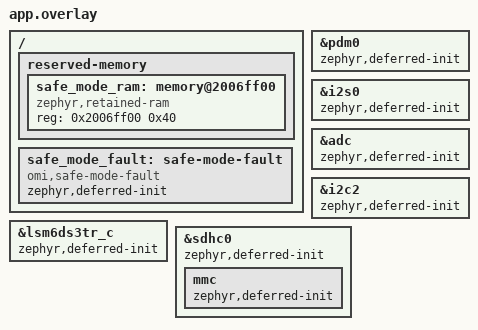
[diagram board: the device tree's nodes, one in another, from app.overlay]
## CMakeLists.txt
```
cmake_minimum_required(VERSION 3.20.0)
find_package(Zephyr REQUIRED HINTS $ENV{ZEPHYR_BASE})
enable_language(C ASM) # OPUS

project(omi)
include(cmake/safe-mode-build.cmake)
zephyr_linker_sources(SECTIONS src/safe_mode.ld)

file(GLOB app_sources
    src/main.c
    src/diagnostics.c
    src/diagnostics_packet.c
    src/boot_telemetry.c
    src/boot_telemetry_logic.c
    src/safe_mode.c
    src/safe_mode_devices.c
    src/mic.c
    src/battery.c
    src/led.c
    src/haptic.c
    src/sd_card.c
    src/spi_flash.c
    src/settings.c
    src/feedback.c
    src/wdog_facade.c
    src/rtc.c
    src/imu.c
)

if(CONFIG_OMI_ENABLE_T5838_AAD)
    # Hardware AAD is integrated into mic.c; t5838_aad.c is the low-level driver.
    list(APPEND app_sources src/t5838_aad.c)
endif()

if(CONFIG_OMI_SDHC_SPI_CMD12_FIX)
    # Zephyr's SPI SD host driver with the CMD12 reply fix, built instead of the stock one.
    list(APPEND app_sources src/sdfix/sdhc_spi_cmd12_fix.c)
endif()
file(GLOB core_sources
    src/lib/core/config.h
    src/lib/core/codec.c
    src/lib/core/custody.c
    src/lib/core/transport.c
    src/lib/core/battery_guard.c
    src/lib/core/button.c
    src/lib/core/capture_mute.c
    src/lib/core/monitor.c
    src/lib/core/unit_id.c
)

if(CONFIG_OMI_ENABLE_OFFLINE_STORAGE)
    list(APPEND core_sources src/lib/core/storage.c)
endif()

target_sources(app PRIVATE ${core_sources} ${app_sources})
target_include_directories(app PRIVATE
    ${CMAKE_CURRENT_SOURCE_DIR}/src
    ${CMAKE_CURRENT_SOURCE_DIR}/src/lib/core
    ${CMAKE_CURRENT_SOURCE_DIR}/../common
)

if(CONFIG_OMI_CODEC_OPUS)
    add_subdirectory(src/lib/core/lib/opus-1.2.1/)
    target_link_libraries(app PRIVATE opus_codec)
endif()
```

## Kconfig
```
source "Kconfig.zephyr"

menu "Omi Features Configuration"

config OMI_CODEC_OPUS
    bool "Opus Audio Codec"
    help
        "Enable the Opus audio codec support."
    default n

config OMI_ENABLE_OFFLINE_STORAGE
	bool "Offline SD Card Storage"
    help
        "Enable the offline storage support. Requires a SD Card."
	default n

config OMI_ENABLE_ACCELEROMETER
    bool "Accelerometer Support"
    help
        "Enable the accelerometer support."
    default n

config OMI_ENABLE_BUTTON
    bool "Button support"
    help
        "Enable the software button support."
    default n

config OMI_ENABLE_SPEAKER
    bool "Enable the speaker"
    help
        "Enable the speaker support."
    default n

config OMI_ENABLE_BATTERY
    bool "Enable the battery"
    help
        "Enable the battery support."
    default n

config OMI_ENABLE_USB
    bool "Enable the usb"
    help
        "Enable the USB power check support."
    default n

config OMI_ENABLE_HAPTIC
    bool "Enable the haptic"
    help
        "Enable the haptic support."
    default n

config OMI_ENABLE_RFSW_CTRL
    bool "Enable RFSwitch Control"
    help
        "Enable RFSwitch Control support."
    default y

config OMI_ENABLE_MONITOR
    bool "Enable monitoring/metrics system"
    help
        "Enable the monitoring system for debugging and metrics collection.
         Disable in production to save power, RAM, and flash space."
    default n

config OMI_ENABLE_T5838_AAD
    bool "Enable T5838 hardware AAD (ultra-low-power mic sleep)"
    default n
    help
        "After the configured silence interval, pause the PDM clock so the
         T5838 MEMS microphone enters its built-in Acoustic Activity Detection
         mode (~15 µA). The mic hardware monitors sound and asserts the WAKE
         pin when it detects acoustic activity, at which point the driver
         resumes PDM and audio streaming.
         Requires THSEL (P1.5) and WAKE (P1.2) to be wired to the T5838."

config OMI_VAD_ABS_THRESHOLD
    int "AAD silence-detection average absolute amplitude threshold"
    range 1 32767
    default 600
    depends on OMI_ENABLE_T5838_AAD
    help
        "An average absolute amplitude at or above this value resets the
         silence timer used to decide when to enter T5838 hardware AAD sleep.
         This does not gate or drop streamed audio while the mic is active."

config OMI_VAD_HOLD_MS
    int "AAD silence hold time before hardware sleep (ms)"
    range 500 30000
    default 3000
    depends on OMI_ENABLE_T5838_AAD
    help
        "Amount of continuous below-threshold silence before entering T5838
         hardware AAD sleep. This does not gate or drop streamed audio while
         the mic is active."

config OMI_AAD_SETTLE_MS
    int "T5838 AAD settle time before arming WAKE (ms)"
    range 100 3000
    default 800
    depends on OMI_ENABLE_T5838_AAD
    help
        "Time to wait after clocking the T5838 into hardware AAD sleep before
         arming the WAKE interrupt. Lets the mic settle its noise floor and
         swallow the entry transient so it does not immediately false-wake."

config OMI_WATCHDOG_TIMEOUT_MS
    int "Watchdog timeout (ms)"
    range 5000 300000
    default 30000
    help
        "Watchdog reset timeout in milliseconds. Increase this when boot-time
         operations can run longer (e.g. SD/LFS pre-warm) to avoid false
         watchdog resets."

config OMI_SDHC_SPI_CMD12_FIX
    bool "SPI SD host driver with the CMD12 reply fix"
    depends on DT_HAS_ZEPHYR_SDHC_SPI_SLOT_ENABLED
    depends on !SPI_SDHC
    select SPI
    select CRC
    select SDHC_SUPPORTS_SPI_MODE
    default n
    help
        "Builds src/sdfix/sdhc_spi_cmd12_fix.c, Zephyr's drivers/sdhc/sdhc_spi.c
         with the reply to CMD12 (STOP_TRANSMISSION) decoded even when it starts
         partway through a byte, instead of the stock driver. Without it every
         multi-block read fails with -EINVAL on cards that answer that way.
         Needs CONFIG_SPI_SDHC=n."
config OMI_SAFE_MODE_BOOT_LIMIT
    int "Failed boots before recovery"
    range 1 20
    default 3

config OMI_SAFE_MODE_GOOD_UPTIME_S
    int "Healthy main-loop uptime before GOOD (seconds)"
    range 1 3600
    default 60

config OMI_FAULT_INJECT
    bool "DEVELOPMENT ONLY: safe-mode fault injection"
    depends on DEBUG
    default n
    help
      Also requires -DOMI_DEVELOPMENT_BUILD=ON. Release builds reject this.

choice OMI_FAULT_INJECT_KIND
    prompt "Fault to inject on every normal trial"
    depends on OMI_FAULT_INJECT
    default OMI_FAULT_INJECT_HARD_FAULT

config OMI_FAULT_INJECT_HARD_FAULT
    bool "Fatal error before BLE"
config OMI_FAULT_INJECT_DRIVER_HANG
    bool "Deferred driver-init hang"
config OMI_FAULT_INJECT_SETTINGS_HANG
    bool "Hang in app_settings_init"
config OMI_FAULT_INJECT_WDT_STARVE
    bool "Stop feeding WDT at uptime 30 seconds"
endchoice

config OMI_FAULT_INJECT_HARD_FAULT_DELAY_MS
    int "Dwell before the injected fatal error"
    depends on OMI_FAULT_INJECT_HARD_FAULT
    default 0
    help
      Sleep this long between the fault witness line and the fatal error,
      still before BLE, so a bench observer polling over SWD can sample the
      witness on every failing boot.

endmenu
```

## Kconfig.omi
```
menu "Omi2 Features Configuration"

config OMI2_CODEC_OPUS
    bool "Opus Audio Codec"
    help
        "Enable the Opus audio codec support."
    default n

config OMI2_ENABLE_OFFLINE_STORAGE
    bool "Offline SD Card Storage"
    select DISK_ACCESS
    select FILE_SYSTEM
    select FAT_FILESYSTEM_ELM
    select FS_FATFS_MOUNT_MKFS
    select FS_FATFS_EXFAT
    help
        "Enable the offline storage support. Requires a SD Card."
    default n

config OMI2_ENABLE_ACCELEROMETER
    bool "Accelerometer Support"
    help
        "Enable the accelerometer support."
    default n

config OMI2_ENABLE_BUTTON
    bool "Button support"
    help
        "Enable the software button support."
    default n

config OMI2_ENABLE_SPEAKER
    bool "Enable the speaker"
    help
        "Enable the speaker support."
    default n

config OMI2_ENABLE_BATTERY
    bool "Enable the battery"
    help
        "Enable the battery support."
    default n

config OMI2_ENABLE_USB
    bool "Enable the usb"
    help
        "Enable the USB power check support."
    default n

config OMI2_ENABLE_HAPTIC
    bool "Enable the haptic"
    help
        "Enable the haptic support."
    default n

endmenu
```

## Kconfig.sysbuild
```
#
# Copyright (c) 2023 Nordic Semiconductor
#
# SPDX-License-Identifier: LicenseRef-Nordic-5-Clause
#

source "${ZEPHYR_BASE}/share/sysbuild/Kconfig"

config NRF_DEFAULT_IPC_RADIO
	default y

config NETCORE_IPC_RADIO_BT_HCI_IPC
	default y
```

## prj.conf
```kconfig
CONFIG_SERIAL=y

CONFIG_GPIO=y
CONFIG_INPUT=y
CONFIG_I2C=y
# CONFIG_I2C_SHELL=y
CONFIG_SPI=y
CONFIG_SPI_NOR=y
# CONFIG_SPI_SHELL=y
CONFIG_SETTINGS=y
CONFIG_SETTINGS_NVS=y
CONFIG_NVS=y

CONFIG_PM_DEVICE=y
# CONFIG_PM_DEVICE_RUNTIME=y
CONFIG_ADC=y
CONFIG_ADC_ASYNC=y
CONFIG_ADC_NRFX_SAADC=y
CONFIG_AUDIO=y
CONFIG_AUDIO_DMIC=y
CONFIG_FLASH=y
CONFIG_FLASH_JESD216_API=y
CONFIG_DISK_DRIVER_SDMMC=y
CONFIG_SENSOR=y
CONFIG_REGULATOR=y
CONFIG_ENTROPY_GENERATOR=y

CONFIG_BT=y
CONFIG_BT_SMP=y
CONFIG_BT_PERIPHERAL=y
CONFIG_BT_DIS=n
CONFIG_BT_BAS=n
# CONFIG_BT_DEVICE_NAME="OMI" # configurated bellow
# CONFIG_BT_DEVICE_APPEARANCE=768 # TODO: conflict
CONFIG_CBPRINTF_FP_SUPPORT=y

CONFIG_NCS_SAMPLE_MCUMGR_BT_OTA_DFU=y
CONFIG_MCUMGR_GRP_IMG_ALLOW_ERASE_PENDING=y
# BT NUS shell: controlled by CONFIG_OMI_ENABLE_BT_LOG
CONFIG_SHELL=y
CONFIG_SHELL_BT_NUS=n
CONFIG_SHELL_BT_NUS_LOG_LEVEL_INF=n
CONFIG_SHELL_LOG_BACKEND=y
# CONFIG_SHELL_BACKEND_DUMMY=y

CONFIG_POWEROFF=y

# CONFIG_T5838_LOG_LEVEL_DBG=y
# CONFIG_T5838_AAD_TRIGGER=y

# file system
# CONFIG_MAIN_STACK_SIZE=2048
CONFIG_FILE_SYSTEM=y
# CONFIG_FILE_SYSTEM_EXT2=y

# LittleFS formats itself on first mount - no explicit mkfs needed
# CONFIG_FILE_SYSTEM_MKFS is not set
# CONFIG_FS_FATFS_MKFS is not set
# CONFIG_TEST_RANDOM_GENERATOR=y

CONFIG_DISK_ACCESS=y
CONFIG_DISK_DRIVER_SDMMC=y

# FAT filesystem automatically detects partitions
# CONFIG_EXT2_DISK_STARTING_SECTOR=2082

# Memories
CONFIG_MAIN_STACK_SIZE=4096
CONFIG_SYSTEM_WORKQUEUE_STACK_SIZE=4096

# Kernel options
CONFIG_ENTROPY_GENERATOR=y
CONFIG_POSIX_CLOCK=y

CONFIG_INIT_STACKS=y
CONFIG_HEAP_MEM_POOL_SIZE=40000

#
# Hardware settings
#

CONFIG_PWM=y
CONFIG_GPIO=y
CONFIG_ADC=y

#
# Audio (new)
#
CONFIG_I2S=y
CONFIG_I2S_NRFX=y
CONFIG_SPI_NRFX=y
CONFIG_AUDIO=y
CONFIG_AUDIO_DMIC=y
CONFIG_AUDIO_DMIC_NRFX_PDM=y
CONFIG_NRFX_PDM0=y  # PDM microphone

# Watchdog Timer
CONFIG_WATCHDOG=y
CONFIG_WDT_DISABLE_AT_BOOT=n

# To flash via dev board
#CONFIG_BUILD_OUTPUT_UF2=n
#CONFIG_USE_DT_CODE_PARTITION=n

#
# Bluetooth settings
#

CONFIG_BT=y
CONFIG_BT_PERIPHERAL=y
CONFIG_BT_MAX_CONN=1
# CONFIG_BT_EXT_ADV_MAX_ADV_SET=2
CONFIG_BT_MAX_PAIRED=1
CONFIG_BT_DEVICE_APPEARANCE=22
CONFIG_BT_GATT_DYNAMIC_DB=y

#
# Max transmit power supported by nRF52840
#

CONFIG_BT_CTLR_TX_PWR_ANTENNA=8
CONFIG_BT_PHY_UPDATE=y

#
# Battery and Device Information services
#

CONFIG_BT_BAS=y
CONFIG_BT_DIS=y
CONFIG_BT_DIS_PNP=n
CONFIG_BT_DEVICE_NAME="Omi"
CONFIG_BT_DIS_MODEL="Omi CV 1"
CONFIG_BT_DIS_MANUF="Based Hardware"
CONFIG_BT_DIS_FW_REV=y
CONFIG_BT_DIS_HW_REV=y
CONFIG_BT_DIS_FW_REV_STR="3.0.15"
CONFIG_BT_DIS_HW_REV_STR="5.0"

#
# Large BLE packets / BLE Buffers 
#
# CONFIG_BT_GATT_CLIENT=y
# CONFIG_BT_THROUGHPUT=y

CONFIG_BT_L2CAP_TX_MTU=498

CONFIG_BT_CTLR_DATA_LENGTH_MAX=251
CONFIG_BT_CTLR_PHY_2M=y
CONFIG_BT_CTLR_PHY_CODED=y
CONFIG_BT_CTLR_SDC_MAX_CONN_EVENT_LEN_DEFAULT=400000
CONFIG_BT_CONN_TX_MAX=20
CONFIG_BT_L2CAP_TX_BUF_COUNT=20
CONFIG_BT_BUF_ACL_RX_SIZE=1024
CONFIG_BT_BUF_ACL_TX_SIZE=2048
CONFIG_BT_ATT_TX_COUNT=20
# CONFIG_BT_EXT_ADV=y
# CONFIG_BT_PER_ADV=y
# CONFIG_BT_OBSERVER=y
# CONFIG_BT_ATT_PREPARE_COUNT=2
CONFIG_BT_USER_DATA_LEN_UPDATE=y
CONFIG_BT_USER_PHY_UPDATE=y
CONFIG_BT_AUTO_DATA_LEN_UPDATE=y
CONFIG_BT_AUTO_PHY_UPDATE=y
CONFIG_BT_GATT_AUTO_UPDATE_MTU=y

CONFIG_BT_GATT_CLIENT=y

# Automatically request preferred connection parameters (default is y, but explicit)
CONFIG_BT_GAP_AUTO_UPDATE_CONN_PARAMS=y

# Set preferred connection parameters
# 7.5ms
CONFIG_BT_PERIPHERAL_PREF_MIN_INT=6
# 15ms (was 30ms — tighter interval = more events/sec = higher throughput)
CONFIG_BT_PERIPHERAL_PREF_MAX_INT=12
CONFIG_BT_PERIPHERAL_PREF_LATENCY=0
# 4 seconds
CONFIG_BT_PERIPHERAL_PREF_TIMEOUT=400

CONFIG_FPU=y
CONFIG_NORDIC_QSPI_NOR=y
# CONFIG_BOARD_ENABLE_DCDC=y
#

#
# Console
#
# Y to enable console log
CONFIG_CONSOLE=y
CONFIG_PRINTK=y
CONFIG_UART_CONSOLE=y
# CONFIG_SHELL_BACKEND_SERIAL=y

#
# Logs
#

## Enable the lines below to enable logs via UART/USB
CONFIG_LOG=y
CONFIG_LOG_PRINTK=y
CONFIG_UART_CONSOLE=y
CONFIG_LOG_PROCESS_THREAD_PRIORITY=5
CONFIG_LOG_PROCESS_THREAD_CUSTOM_PRIORITY=y
#
# CONFIG_LOG_MODE_IMMEDIATE=y
# CONFIG_SENSOR_LOG_LEVEL_DBG=y
# CONFIG_FLASH_LOG_LEVEL_DBG=y
# CONFIG_FS_LOG_LEVEL_DBG=y


#
# Enable logging (set level to DBG=4, INF=3, WRN=2, ERR=1)
# CONFIG_LOG_DEFAULT_LEVEL=3

#
# Log level and buffer size
#

# CONFIG_LOG_OVERRIDE_LEVEL=4
# CONFIG_LOG_BUFFER_SIZE=32000
# CONFIG_LOG_PROCESS_THREAD_STACK_SIZE=4096

#
# Debug
#

# CONFIG_DEBUG=y
# CONFIG_DEBUG_OPTIMIZATIONS=y
# CONFIG_SERIAL=y

#
# Debug (This value breaks some builds)
#

# CONFIG_ASSERT=y

#
# BT log configuration
#

# CONFIG_BT_DEBUG_LOG=y
# CONFIG_BT_L2CAP_LOG_LEVEL_DBG=y
# CONFIG_BT_LOG_LEVEL_DBG=y

# CONFIG_BT_RX_STACK_SIZE=4096
# CONFIG_BT_CTLR_RX_PRIO_STACK_SIZE=4096
# CONFIG_BT_DEBUG_LOG=y
# CONFIG_BT_RX_STACK_SIZE=4096
# CONFIG_BT_CTLR_RX_PRIO_STACK_SIZE=4096

#
# SD Card Support (all devices required)
#

CONFIG_DISK_ACCESS=y
CONFIG_FILE_SYSTEM=y

# LittleFS for SD NAND (power-loss safe, no FAT dirty-bit issues)
CONFIG_FILE_SYSTEM_LITTLEFS=y

# FAT disabled - SD NAND + FATFS is unstable (no wear leveling, power-loss unsafe)
# CONFIG_FAT_FILESYSTEM_ELM is not set
# CONFIG_FS_FATFS_MOUNT_MKFS is not set
CONFIG_MAIN_STACK_SIZE=4096
CONFIG_DISK_DRIVER_SDMMC=y
# CONFIG_SPI=y
# CONFIG_HEAP_MEM_POOL_SIZE=512 # disabled by conflicting

#
# Disable unused peripherals
#
CONFIG_I2C=n
# CONFIG_NRFX_TWIM0=n
# CONFIG_NRFX_TWIM1=n

#
# LSM6DSL sensor (accelerometer and gyroscope)
#
CONFIG_LSM6DSL=y
CONFIG_LSM6DSL_ENABLE_TEMP=n
# CONFIG_LSM6DSL_TRIGGER_GLOBAL_THREAD=y
CONFIG_SENSOR=y

#
# Speaker
#
CONFIG_I2S=y
CONFIG_I2S_NRFX=y
CONFIG_SPI_NRFX=y

#
# NFC (in the future)
#

# CONFIG_NFC_T2T_NRFXLIB=y
# CONFIG_NFC_NDEF=y
# CONFIG_NFC_NDEF_MSG=y
# CONFIG_NFC_NDEF_RECORD=y
# CONFIG_NFC_NDEF_URI_MSG=y
# CONFIG_NFC_NDEF_URI_REC=y
# CONFIG_HWINFO=y

#
#EVERYTHING ELSE
#

CONFIG_RING_BUFFER=y

CONFIG_PM_DEVICE=y
# CONFIG_NRFX_USBD=y

# CONFIG_FLASH=y
#

#
# OMI features configuration
#
CONFIG_OMI_CODEC_OPUS=y
CONFIG_OMI_ENABLE_OFFLINE_STORAGE=y
CONFIG_OMI_ENABLE_ACCELEROMETER=n
CONFIG_OMI_ENABLE_BUTTON=y
CONFIG_OMI_ENABLE_SPEAKER=n
CONFIG_OMI_ENABLE_BATTERY=y
CONFIG_OMI_ENABLE_USB=n
CONFIG_OMI_ENABLE_HAPTIC=y
CONFIG_OMI_ENABLE_RFSW_CTRL=y
CONFIG_OMI_ENABLE_MONITOR=n
```

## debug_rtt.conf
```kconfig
# Debug overlay for AAD bring-up.
# Routes logs + console to SEGGER RTT so they can be read over the debugger
# with no UART wiring. APPROTECT is left unlocked (default) for SWD access.

CONFIG_USE_SEGGER_RTT=y
CONFIG_LOG_BACKEND_RTT=y
CONFIG_LOG_BACKEND_UART=n
CONFIG_RTT_CONSOLE=y
CONFIG_UART_CONSOLE=n
CONFIG_SEGGER_RTT_BUFFER_SIZE_UP=16384
CONFIG_LOG_BACKEND_RTT_MODE_BLOCK=y
CONFIG_LOG_BUFFER_SIZE=8192
CONFIG_LOG_DEFAULT_LEVEL=3

# Shorten VAD hold so the device drops into hardware AAD after 3s of silence
# (default 10s) for faster test iteration.
CONFIG_OMI_VAD_HOLD_MS=3000
```

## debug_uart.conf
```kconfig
# Debug overlay: log over UART console (P0.03 TX / P0.02 RX @115200) instead of RTT.
# prj.conf already enables CONFIG_LOG + CONFIG_UART_CONSOLE.
CONFIG_OMI_VAD_HOLD_MS=10000
CONFIG_OMI_AAD_SETTLE_MS=800
CONFIG_OMI_DEBUG_FAKE_RTC=y
CONFIG_OMI_AAD_TEST_MODE=0
CONFIG_OMI_AAD_POWER_OFF_MIC=n
```

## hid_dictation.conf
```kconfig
# Omi CV1 HID dictation PROTOTYPE build overlay.
#
# NOT for production: append to the production omi.conf via
#   west build ... -- -DEXTRA_CONF_FILE=<this file>
# or use scripts/ci/build-cv1-hid-prototype.sh, which wires everything up.
#
# What this changes vs. the stock build:
#  - compiles in the opt-in dictation control-plane + (after an explicit,
#    RAM-only app opt-in) a standard BLE HID keyboard service;
#  - HID characteristics require an encrypted link (standard for HID hosts);
#  - bond storage enabled so a paired HID host can reconnect;
#  - GAP appearance becomes "keyboard" so hosts classify the pendant.
# Stock behavior is unchanged until the app enables the prototype, and a
# power cycle always clears the opt-in (documented recovery path).

CONFIG_OMI_ENABLE_HID_DICTATION=y

CONFIG_BT_HIDS=y
CONFIG_BT_CONN_CTX=y
CONFIG_BT_HIDS_MAX_CLIENT_COUNT=1
CONFIG_BT_HIDS_INPUT_REP_MAX=1
CONFIG_BT_HIDS_OUTPUT_REP_MAX=1
CONFIG_BT_HIDS_DEFAULT_PERM_RW_ENCRYPT=y

CONFIG_BT_GATT_SERVICE_CHANGED=y
CONFIG_BT_SETTINGS=y
CONFIG_BT_KEYS_OVERWRITE_OLDEST=y

CONFIG_BT_DEVICE_APPEARANCE=961
```

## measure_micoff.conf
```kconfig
# Power measurement: force the mic into hardware AAD sleep forever (mic-off floor).
CONFIG_OMI_AAD_TEST_MODE=1
CONFIG_OMI_VAD_HOLD_MS=1000
CONFIG_OMI_AAD_SETTLE_MS=800
```

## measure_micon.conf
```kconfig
# Power measurement: mic runs continuously, never enters AAD (mic-on floor = soft AAD).
CONFIG_OMI_AAD_TEST_MODE=2
```

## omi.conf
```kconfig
CONFIG_SERIAL=y
CONFIG_GPIO=y
CONFIG_PWM=y
CONFIG_INPUT=y
CONFIG_I2C=y
CONFIG_SPI=y
CONFIG_SPI_NOR=y
CONFIG_SETTINGS=y
CONFIG_SETTINGS_NVS=y
CONFIG_NVS=y

CONFIG_PM_DEVICE=y
CONFIG_ADC=y
CONFIG_ADC_ASYNC=y
CONFIG_ADC_NRFX_SAADC=y
CONFIG_AUDIO=y
CONFIG_AUDIO_DMIC=y
CONFIG_FLASH=y
CONFIG_FLASH_JESD216_API=y
CONFIG_DISK_DRIVER_SDMMC=y
CONFIG_SENSOR=y
CONFIG_REGULATOR=y
CONFIG_ENTROPY_GENERATOR=y

CONFIG_RING_BUFFER=y

CONFIG_BT=y
CONFIG_BT_SMP=y
CONFIG_BT_PERIPHERAL=y
CONFIG_BT_DIS=n
CONFIG_BT_BAS=n
# CONFIG_BT_DEVICE_NAME="OMI" # configurated bellow
# CONFIG_BT_DEVICE_APPEARANCE=768 # TODO: conflict
CONFIG_CBPRINTF_FP_SUPPORT=y

CONFIG_NCS_SAMPLE_MCUMGR_BT_OTA_DFU=y
CONFIG_MCUMGR_GRP_IMG_ALLOW_ERASE_PENDING=y
# BT NUS shell: controlled by CONFIG_OMI_ENABLE_BT_LOG
CONFIG_SHELL=n
CONFIG_SHELL_BT_NUS=n
CONFIG_SHELL_BT_NUS_LOG_LEVEL_INF=n
CONFIG_SHELL_LOG_BACKEND=n

CONFIG_POWEROFF=y

# file system
# CONFIG_MAIN_STACK_SIZE=2048
CONFIG_FILE_SYSTEM=y
CONFIG_DISK_ACCESS=y
CONFIG_DISK_DRIVER_SDMMC=y
# SD card over SPI: Zephyr's driver with the CMD12 reply fix (src/sdfix), not the stock one.
CONFIG_SPI_SDHC=n
CONFIG_OMI_SDHC_SPI_CMD12_FIX=y

# Memories
CONFIG_MAIN_STACK_SIZE=4096
CONFIG_SYSTEM_WORKQUEUE_STACK_SIZE=4096

# Kernel options
CONFIG_ENTROPY_GENERATOR=y
CONFIG_POSIX_CLOCK=y

CONFIG_INIT_STACKS=y
CONFIG_HEAP_MEM_POOL_SIZE=40000

#
# Audio (new)
#
CONFIG_I2S=y
CONFIG_I2S_NRFX=y
CONFIG_SPI_NRFX=y
CONFIG_AUDIO=y
CONFIG_AUDIO_DMIC=y
CONFIG_AUDIO_DMIC_NRFX_PDM=y
CONFIG_NRFX_PDM0=y  # PDM microphone

# Watchdog Timer
CONFIG_WATCHDOG=y
CONFIG_WDT_DISABLE_AT_BOOT=n

# To flash via dev board
#CONFIG_BUILD_OUTPUT_UF2=n
#CONFIG_USE_DT_CODE_PARTITION=n

#
# Bluetooth settings
#

CONFIG_BT=y
CONFIG_BT_PERIPHERAL=y
CONFIG_BT_MAX_CONN=1
CONFIG_BT_MAX_PAIRED=1
CONFIG_BT_DEVICE_APPEARANCE=22
CONFIG_BT_GATT_DYNAMIC_DB=y
CONFIG_BT_DEVICE_NAME_DYNAMIC=y

#
# nRF5340 BLE controller settings (network core)
#

# BT_CTLR_* options take effect on the network core via sysbuild/ipc_radio.conf,
# not this app-core config. Keep controller tuning in that image configuration.
CONFIG_BT_CTLR_TX_PWR_ANTENNA=8
CONFIG_BT_PHY_UPDATE=y

#
# Battery and Device Information services
#

CONFIG_BT_BAS=y
CONFIG_BT_DIS=y
CONFIG_BT_DIS_PNP=n
CONFIG_BT_DEVICE_NAME="Omi"
CONFIG_BT_DIS_MODEL="Omi CV 1"
CONFIG_BT_DIS_MANUF="Based Hardware"
CONFIG_BT_DIS_FW_REV=y
CONFIG_BT_DIS_HW_REV=y
CONFIG_BT_DIS_FW_REV_STR="3.0.24"
CONFIG_BT_DIS_HW_REV_STR="5.0"
# Per-unit serial (0x2A25) = FICR device ID, set at boot by unit_id.c through
# the DIS settings handler. The static string is only a fallback.
CONFIG_BT_DIS_SERIAL_NUMBER=y
CONFIG_BT_DIS_SERIAL_NUMBER_STR="unknown"
CONFIG_BT_DIS_SETTINGS=y
CONFIG_SETTINGS_RUNTIME=y
CONFIG_HWINFO=y

#
# Large BLE packets / BLE Buffers 
#
# CONFIG_BT_GATT_CLIENT=y
# CONFIG_BT_THROUGHPUT=y

CONFIG_BT_L2CAP_TX_MTU=498

CONFIG_BT_CTLR_DATA_LENGTH_MAX=251
CONFIG_BT_CTLR_PHY_2M=y
CONFIG_BT_CTLR_PHY_CODED=y
CONFIG_BT_CTLR_SDC_MAX_CONN_EVENT_LEN_DEFAULT=400000
CONFIG_BT_CONN_TX_MAX=20
CONFIG_BT_L2CAP_TX_BUF_COUNT=20
CONFIG_BT_BUF_ACL_RX_SIZE=1024
CONFIG_BT_BUF_ACL_TX_SIZE=2048
CONFIG_BT_BUF_ACL_TX_COUNT=10
CONFIG_BT_ATT_TX_COUNT=20
CONFIG_BT_USER_DATA_LEN_UPDATE=y
CONFIG_BT_USER_PHY_UPDATE=y
CONFIG_BT_AUTO_DATA_LEN_UPDATE=y
CONFIG_BT_AUTO_PHY_UPDATE=y
CONFIG_BT_GATT_AUTO_UPDATE_MTU=y

CONFIG_BT_GATT_CLIENT=y

# Automatically request preferred connection parameters (default is y, but explicit)
CONFIG_BT_GAP_AUTO_UPDATE_CONN_PARAMS=y

# Set preferred connection parameters
# 7.5ms
CONFIG_BT_PERIPHERAL_PREF_MIN_INT=6
# 15ms (was 30ms — tighter interval = more events/sec = higher throughput)
CONFIG_BT_PERIPHERAL_PREF_MAX_INT=12
CONFIG_BT_PERIPHERAL_PREF_LATENCY=0
# 6 seconds
CONFIG_BT_PERIPHERAL_PREF_TIMEOUT=600

CONFIG_FPU=y
CONFIG_NORDIC_QSPI_NOR=y
CONFIG_BOARD_ENABLE_DCDC_APP=y
CONFIG_BOARD_ENABLE_DCDC_NET=y

#
# Console
#
# Y to enable console log
CONFIG_CONSOLE=y
CONFIG_PRINTK=y
CONFIG_UART_CONSOLE=y
# CONFIG_SHELL_BACKEND_SERIAL=y

# Keep release output minimal: only explicit printk() lines.
CONFIG_LOG=n

#
# Logs
#

## Enable the lines below to enable logs via UART/USB
# CONFIG_LOG=y
# CONFIG_LOG_PRINTK=y
# CONFIG_UART_CONSOLE=y
# CONFIG_LOG_PROCESS_THREAD_PRIORITY=5
# CONFIG_LOG_PROCESS_THREAD_CUSTOM_PRIORITY=y
#
# CONFIG_LOG_MODE_IMMEDIATE=y
# CONFIG_SENSOR_LOG_LEVEL_DBG=y
# CONFIG_FLASH_LOG_LEVEL_DBG=y
# CONFIG_FS_LOG_LEVEL_DBG=y


#
# Enable logging (set level to DBG=4, INF=3, WRN=2, ERR=1)
# CONFIG_LOG_DEFAULT_LEVEL=3

# LittleFS is currently unused by CV1 storage.
# src/sd_card.c uses a raw-sector SD NAND ring with no filesystem.
CONFIG_FILE_SYSTEM_LITTLEFS=y

#
# Disable unused peripherals
#
CONFIG_I2C=n
# CONFIG_NRFX_TWIM0=n
# CONFIG_NRFX_TWIM1=n

#
# LSM6DSL sensor (accelerometer and gyroscope)
#
CONFIG_LSM6DSL=y
CONFIG_LSM6DSL_ENABLE_TEMP=n

#
# OMI features configuration
#
CONFIG_OMI_CODEC_OPUS=y
CONFIG_OMI_ENABLE_OFFLINE_STORAGE=y
CONFIG_OMI_ENABLE_ACCELEROMETER=n
CONFIG_OMI_ENABLE_BUTTON=y
CONFIG_OMI_ENABLE_SPEAKER=n
CONFIG_OMI_ENABLE_BATTERY=y
CONFIG_OMI_ENABLE_USB=n
CONFIG_OMI_ENABLE_HAPTIC=y
CONFIG_OMI_ENABLE_RFSW_CTRL=y
CONFIG_OMI_ENABLE_MONITOR=n
CONFIG_OMI_ENABLE_T5838_AAD=y
# Silence threshold + hold used only to decide when to enter hardware AAD sleep.
CONFIG_OMI_VAD_ABS_THRESHOLD=250
CONFIG_OMI_VAD_HOLD_MS=10000
CONFIG_OMI_AAD_SETTLE_MS=800

# App-owned recovery observes completed image uploads.
CONFIG_MCUMGR_MGMT_NOTIFICATION_HOOKS=y
CONFIG_MCUMGR_GRP_IMG_STATUS_HOOKS=y

CONFIG_MCUMGR_GRP_IMG_UPLOAD_CHECK_HOOK=y
```

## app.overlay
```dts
/* App only: the shared board DTS and MCUboot's DTS remain unchanged. */
/ {
    reserved-memory {
        #address-cells = <1>;
        #size-cells = <1>;
        ranges;
        safe_mode_ram: memory@2006ff00 {
            compatible = "zephyr,retained-ram";
            reg = <0x2006ff00 0x40>;
        };
    };
};

/* Application only. Recovery never invokes these devices' init functions. */
&pdm0 { zephyr,deferred-init; };
&i2s0 { zephyr,deferred-init; };
&adc { zephyr,deferred-init; };
&i2c2 { zephyr,deferred-init; };
&lsm6ds3tr_c { zephyr,deferred-init; };
&sdhc0 {
    zephyr,deferred-init;
    mmc { zephyr,deferred-init; };
};

/ {
    safe_mode_fault: safe-mode-fault {
        compatible = "omi,safe-mode-fault";
        zephyr,deferred-init;
    };
};
```

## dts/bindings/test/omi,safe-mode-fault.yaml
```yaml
description: Development-only deferred-init hang witness
compatible: "omi,safe-mode-fault"
include: base.yaml
```

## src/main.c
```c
#include <zephyr/kernel.h>
#include <zephyr/logging/log.h>
#include <zephyr/pm/device_runtime.h>
#include <zephyr/shell/shell.h>

#include "lib/core/button.h"
#include "lib/core/codec.h"
#include "lib/core/config.h"
#include "lib/core/feedback.h"
#include "lib/core/haptic.h"
#include "lib/core/led.h"
#include "lib/core/lib/battery/battery.h"
#include "lib/core/mic.h"
#ifdef CONFIG_OMI_ENABLE_MONITOR
#include "lib/core/monitor.h"
#endif
#include "lib/core/settings.h"
#include "lib/core/transport.h"
#ifdef CONFIG_OMI_ENABLE_OFFLINE_STORAGE
#include "lib/core/storage.h"
#endif
#ifndef CONFIG_OMI_NATIVE_SIM
#include <zephyr/fatal.h>
#endif

#include "imu.h"
#include "lib/core/sd_card.h"
#include "rtc.h"
#include "safe_mode.h"
#include "spi_flash.h"
#include "wdog_facade.h"

LOG_MODULE_REGISTER(main, CONFIG_LOG_DEFAULT_LEVEL);

#ifdef CONFIG_OMI_ENABLE_BATTERY
#define BATTERY_FULL_THRESHOLD_PERCENT 98 // 98%
extern uint8_t battery_percentage;
#endif
bool is_connected = false;
bool is_charging = false;
bool is_off = false;
bool blink_toggle = false;

static void codec_handler(uint8_t *data, size_t len)
{
#ifdef CONFIG_OMI_ENABLE_MONITOR
    monitor_inc_broadcast_audio();
#endif
    int err = broadcast_audio_packets(data, len);
    if (err) {
#ifdef CONFIG_OMI_ENABLE_MONITOR
        monitor_inc_broadcast_audio_failed();
#endif
    }
}

static void mic_handler(int16_t *buffer)
{
#ifdef CONFIG_OMI_ENABLE_MONITOR
    // Track total bytes processed (each sample is 2 bytes)
    monitor_inc_mic_buffer();
#endif

    // Hardware AAD (T5838) is handled inside mic.c; the mic callback only
    // forwards audio to the codec here.
    int err = codec_receive_pcm(buffer, MIC_BUFFER_SAMPLES);
    if (err) {
        LOG_ERR("Failed to process PCM data: %d", err);
    }
}

void set_led_state()
{
    // If device is off, turn off all LEDs immediately
    if (is_off) {
        led_off();
        return;
    }

#ifdef CONFIG_OMI_ENABLE_OFFLINE_STORAGE
    // If RTC not synced, blink red to warn user to connect phone app
    if (!rtc_is_valid()) {
        set_led_green(is_charging);
        set_led_blue(!blink_toggle && is_connected);
        set_led_red(blink_toggle);
        blink_toggle = !blink_toggle;
        return;
    }
#endif

    bool green = false;
    bool blue = false;
    bool red = false;

    if (is_charging) {
#ifdef CONFIG_OMI_ENABLE_BATTERY
        // Solid green if battery is full (>= BATTERY_FULL_THRESHOLD_PERCENT)
        if (battery_percentage >= BATTERY_FULL_THRESHOLD_PERCENT) {
            green = true;
        } else
#endif
        {
            green = blink_toggle;
            blue = !blink_toggle && is_connected;
            red = !blink_toggle && !is_connected;
            blink_toggle = !blink_toggle;
        }
    } else {
        blue = is_connected;
        red = !is_connected;
    }

    set_led_green(green);
    set_led_blue(blue);
    set_led_red(red);
}

static int suspend_unused_modules(void)
{
    int err = flash_off();
    if (err) {
        LOG_ERR("Can not suspend the spi flash module: %d", err);
    }

    return 0;
}

int main(void)
{
    int ret;
    printk("Starting omi ...\n");

#ifdef CONFIG_OMI_NATIVE_SIM
    safe_mode_early_boot();
#endif

    // Initialize watchdog first to catch any early freezes
    ret = watchdog_init();
    if (ret) {
        LOG_WRN("Watchdog init failed (err %d), continuing without watchdog", ret);
    }

    /* Decide from validated RAM first. Only cold/invalid RAM (or an interrupted
     * DFU commit) needs the isolated bootstate read. Never load app settings in SAFE.
     */
    safe_mode_restore();
    if (safe_mode_boot()) {
        safe_mode_run();
        return 0;
    }
    int setting_ret = app_settings_init();
    safe_mode_settings_ready(setting_ret);
    ret = safe_mode_devices_init();
    if (ret) {
        LOG_ERR("Deferred device initialization failed (%d)", ret);
        return ret;
    }
#ifdef CONFIG_OMI_FAULT_INJECT_HARD_FAULT
    printk("FAULT_INJECT: fatal before BLE\n");
    k_msleep(CONFIG_OMI_FAULT_INJECT_HARD_FAULT_DELAY_MS);
    __asm__ volatile("udf #0");
    CODE_UNREACHABLE;
#endif

    // Initialize Haptic driver first; this is building up for future of omi turn on sequence - long press to turn on
    // instead of short press
#ifdef CONFIG_OMI_ENABLE_HAPTIC
    ret = haptic_init();
    if (ret) {
        LOG_ERR("Failed to initialize Haptic driver (err %d)", ret);
        error_haptic();
        // Non-critical, continue boot
    } else {
        LOG_INF("Haptic driver initialized");
        play_haptic_milli(100);
    }
#endif

    // Initialize LEDs
    LOG_INF("Initializing LEDs...\n");

    ret = led_start();
    if (ret) {
        LOG_ERR("Failed to initialize LEDs (err %d)", ret);
        error_led_driver();
        return ret;
    }

    // Suspend unused modules
    LOG_PRINTK("\n");
    LOG_INF("Suspending unused modules...\n");
    ret = suspend_unused_modules();
    if (ret) {
        LOG_ERR("Failed to suspend unused modules (err %d)", ret);
        ret = 0;
    }

    // Initialize settings
    LOG_INF("Initializing settings...\n");
    if (setting_ret) {
        LOG_ERR("Failed to initialize settings (err %d)", setting_ret);
    }

    // Initialize RTC from saved epoch
    init_rtc();
    if (!rtc_is_valid()) {
        LOG_WRN("UTC time not synchronized yet");
    }

    (void) lsm6dsl_time_boot_adjust_rtc();

#ifdef CONFIG_OMI_ENABLE_MONITOR
    // Initialize monitoring system
    LOG_INF("Initializing monitoring system...\n");
    ret = monitor_init();
    if (ret) {
        LOG_ERR("Failed to initialize monitoring system (err %d)", ret);
    }
#endif

    if (setting_ret) {
        error_settings();
        app_settings_save_dim_ratio(30);
    }

    // Initialize battery
#ifdef CONFIG_OMI_ENABLE_BATTERY
    ret = battery_init();
    if (ret) {
        LOG_ERR("Battery init failed (err %d)", ret);
        error_battery_init();
        return ret;
    }

    ret = battery_charge_start();
    if (ret) {
        LOG_ERR("Battery failed to start (err %d)", ret);
        error_battery_charge();
        return ret;
    }
    LOG_INF("Battery initialized");
#endif

    // Initialize button
#ifdef CONFIG_OMI_ENABLE_BUTTON
    ret = button_init();
    if (ret) {
        LOG_ERR("Failed to initialize Button (err %d)", ret);
        error_button();
        return ret;
    }
    LOG_INF("Button initialized");
    activate_button_work();
#endif

    // SD Card
    ret = app_sd_init();
    if (ret) {
        LOG_ERR("Failed to initialize SD Card (err %d)", ret);
        error_sd_card();
        return ret;
    }

#ifdef CONFIG_OMI_ENABLE_OFFLINE_STORAGE
    // Initialize storage service for offline audio
    ret = storage_init();
    if (ret) {
        LOG_ERR("Failed to initialize storage service (err %d)", ret);
        error_storage();
        // Non-critical, continue boot
    } else {
        LOG_INF("Storage service initialized");
    }
#endif

    // Indicate transport initialization
    LOG_PRINTK("\n");
    LOG_INF("Initializing transport...\n");

    // Start transport
    int transportErr;
    transportErr = transport_start();
    if (transportErr) {
        LOG_ERR("Failed to start transport (err %d)", transportErr);
        error_transport();
        return transportErr;
    }

    // Initialize codec
    LOG_INF("Initializing codec...\n");

    // Set codec callback
    set_codec_callback(codec_handler);
    ret = codec_start();
    if (ret) {
        LOG_ERR("Failed to start codec: %d", ret);
        error_codec();
        return ret;
    }

    // Initialize microphone
    LOG_INF("Initializing microphone...\n");
    set_mic_callback(mic_handler);
    ret = mic_start();
    if (ret) {
        LOG_ERR("Failed to start microphone: %d", ret);
        error_microphone();
        return ret;
    }
    // Hardware AAD (T5838) is started inside mic_start().

    LOG_INF("Device initialized successfully\n");

    safe_mode_main_loop_ready(transport_advertising_started());
    while (1) {
#ifdef CONFIG_OMI_FAULT_INJECT_WDT_STARVE
        if (k_uptime_get() >= 30000) {
            printk("FAULT_INJECT: watchdog starvation\n");
            for (;;) {
                k_msleep(1000);
            }
        }
#endif
        safe_mode_poll();
        watchdog_feed();
#ifdef CONFIG_OMI_ENABLE_MONITOR
        monitor_log_metrics();
#endif

        set_led_state();
        k_msleep(1000);
    }

    printk("Exiting omi...");
    return 0;
}
```

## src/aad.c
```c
/*
 * AAD + VAD gate for Omi
 *
 * Owns voice-activity detection (VAD) state.  main.c calls
 * aad_process_audio() from the mic callback to decide whether
 * a frame should be forwarded to the codec or discarded.
 *
 * During VAD silence the SD card may be suspended to save power.
 * A dedicated thread manages SD lifecycle and auto-resumes on
 * BLE connect.  The T5838 WAKE pin (P1.2) is monitored via GPIO
 * ISR to reset VAD debounce on acoustic activity.
 */

#include "aad.h"

#include <string.h>
#include <zephyr/device.h>
#include <zephyr/devicetree.h>
#include <zephyr/drivers/gpio.h>
#include <zephyr/kernel.h>
#include <zephyr/logging/log.h>
#include <zephyr/sys/atomic.h>

#include "lib/core/codec.h"
#include "lib/core/config.h"

LOG_MODULE_REGISTER(aad, CONFIG_LOG_DEFAULT_LEVEL);

/* ---- DTS GPIO spec for WAKE pin ---- */
static const struct gpio_dt_spec pin_wake = GPIO_DT_SPEC_GET_OR(DT_NODELABEL(pdm_wake_pin), gpios, {0});
static struct gpio_callback wake_cb_data;

/* ---- Thread plumbing ---- */
#define AAD_THREAD_STACK_SIZE 1024
#define AAD_THREAD_PRIORITY 5

static K_THREAD_STACK_DEFINE(aad_stack, AAD_THREAD_STACK_SIZE);
static struct k_thread aad_thread_data;
static k_tid_t aad_tid;

static K_SEM_DEFINE(aad_sem, 0, 1);

/* ---- Atomic flags (ISR / cross-thread safe) ---- */
static atomic_t wake_pending = ATOMIC_INIT(0);
static atomic_t wake_consumed = ATOMIC_INIT(0);


/* ---- VAD state (mic callback context only) ---- */
static bool vad_is_recording = false;
static bool vad_sleeping = false;
static uint16_t vad_voice_streak = 0;
static int64_t vad_last_voice_ms = 0;
static int64_t vad_next_status_ms = 0;

/* ---- Pre-roll ring buffer ---- */
/* 8 frames * 100 ms/frame ~= 0.8 s pre-roll. */
#define VAD_PREROLL_FRAMES 8
/* Replay/backlog depth (also 0.8 s). With paced one-frame callbacks,
 * this avoids dropping transition speech while staying within RAM budget. */
#define VAD_PREROLL_FLUSH_MAX_FRAMES 8
static int16_t vad_preroll_buf[VAD_PREROLL_FRAMES][MIC_BUFFER_SAMPLES];
static uint8_t vad_preroll_wr = 0;
static uint8_t vad_preroll_cnt = 0;
static uint8_t vad_preroll_flush_rd = 0;
static uint8_t vad_preroll_flush_pending = 0;
static int16_t vad_live_backlog_buf[VAD_PREROLL_FLUSH_MAX_FRAMES][MIC_BUFFER_SAMPLES];
static uint8_t vad_live_backlog_rd = 0;
static uint8_t vad_live_backlog_wr = 0;
static uint8_t vad_live_backlog_cnt = 0;

#define VAD_STATUS_LOG_INTERVAL_MS 2000

/* ---- Helpers ---- */

static void preroll_reset(void)
{
    vad_preroll_wr = 0;
    vad_preroll_cnt = 0;
    vad_preroll_flush_rd = 0;
    vad_preroll_flush_pending = 0;
    vad_live_backlog_rd = 0;
    vad_live_backlog_wr = 0;
    vad_live_backlog_cnt = 0;
}

static bool live_backlog_push(const int16_t *buf)
{
    if (vad_live_backlog_cnt >= VAD_PREROLL_FLUSH_MAX_FRAMES) {
        LOG_ERR("VAD: live backlog overflow (cnt=%u)", vad_live_backlog_cnt);
        return false;
    }

    memcpy(vad_live_backlog_buf[vad_live_backlog_wr], buf, sizeof(vad_live_backlog_buf[0]));
    vad_live_backlog_wr = (vad_live_backlog_wr + 1) % VAD_PREROLL_FLUSH_MAX_FRAMES;
    vad_live_backlog_cnt++;
    return true;
}

static void live_backlog_flush_one(void)
{
    if (vad_live_backlog_cnt == 0) {
        return;
    }

    int err = codec_receive_pcm(vad_live_backlog_buf[vad_live_backlog_rd], MIC_BUFFER_SAMPLES);
    if (err) {
        LOG_ERR("VAD: live backlog flush failed (pending=%u): %d", vad_live_backlog_cnt, err);
        return;
    }

    vad_live_backlog_rd = (vad_live_backlog_rd + 1) % VAD_PREROLL_FLUSH_MAX_FRAMES;
    vad_live_backlog_cnt--;
}

static void preroll_store(const int16_t *buf)
{
    memcpy(vad_preroll_buf[vad_preroll_wr], buf, sizeof(vad_preroll_buf[0]));
    vad_preroll_wr = (vad_preroll_wr + 1) % VAD_PREROLL_FRAMES;
    if (vad_preroll_cnt < VAD_PREROLL_FRAMES) {
        vad_preroll_cnt++;
    }
}

static void preroll_queue_flush(void)
{
    if (vad_preroll_cnt == 0) {
        return;
    }
    uint8_t frames_to_flush = vad_preroll_cnt;
    if (frames_to_flush > VAD_PREROLL_FLUSH_MAX_FRAMES) {
        frames_to_flush = VAD_PREROLL_FLUSH_MAX_FRAMES;
    }

    /* Keep the most recent buffered audio when truncating flush burst. */
    vad_preroll_flush_rd = (vad_preroll_wr + VAD_PREROLL_FRAMES - frames_to_flush) % VAD_PREROLL_FRAMES;
    vad_preroll_flush_pending = frames_to_flush;

    uint8_t dropped = (vad_preroll_cnt > frames_to_flush) ? (vad_preroll_cnt - frames_to_flush) : 0;
    LOG_INF("VAD: queued %u/%u pre-roll frame(s), dropped %u", frames_to_flush, vad_preroll_cnt, dropped);

    /* Reset capture ring state; queued frames remain accessible via
     * vad_preroll_flush_rd + vad_preroll_flush_pending. */
    vad_preroll_wr = 0;
    vad_preroll_cnt = 0;
}

static void preroll_push_one(void)
{
    if (vad_preroll_flush_pending == 0) {
        return;
    }

    uint8_t idx = vad_preroll_flush_rd;
    int err = codec_receive_pcm(vad_preroll_buf[idx], MIC_BUFFER_SAMPLES);
    if (err) {
        LOG_ERR("Preroll push failed (pending=%u): %d", vad_preroll_flush_pending, err);
        vad_preroll_flush_pending = 0;
        return;
    }

    vad_preroll_flush_rd = (vad_preroll_flush_rd + 1) % VAD_PREROLL_FRAMES;
    vad_preroll_flush_pending--;

    if (vad_preroll_flush_pending == 0) {
        LOG_INF("VAD: pre-roll flush complete");
    }
}

static uint32_t avg_abs_amplitude(const int16_t *buf, size_t n)
{
    if (n == 0) {
        return 0;
    }
    uint64_t sum = 0;
    for (size_t i = 0; i < n; i++) {
        int32_t s = buf[i];
        sum += (uint32_t) (s < 0 ? -s : s);
    }
    return (uint32_t) (sum / n);
}

/* ---- WAKE pin ISR ---- */

static void wake_pin_isr(const struct device *dev, struct gpio_callback *cb, uint32_t pins)
{
    ARG_UNUSED(dev);
    ARG_UNUSED(cb);
    ARG_UNUSED(pins);

    atomic_set(&wake_pending, 1);
    k_sem_give(&aad_sem);
}

/* ---- Handler thread (SD suspend / resume) ---- */

static void aad_thread_fn(void *p1, void *p2, void *p3)
{
    ARG_UNUSED(p1);
    ARG_UNUSED(p2);
    ARG_UNUSED(p3);

    LOG_INF("AAD handler thread running");

    while (1) {
        k_sem_take(&aad_sem, K_MSEC(100));

        /* WAKE event from ISR */
        if (atomic_cas(&wake_pending, 1, 0)) {
            atomic_set(&wake_consumed, 1);
            LOG_INF("AAD: WAKE detected");
        }
    }
}

/* ================================================================
 * Public API
 * ================================================================ */

bool aad_process_audio(int16_t *buffer, size_t sample_count)
{
    /* WAKE pin event -> reset VAD debounce */
    if (atomic_cas(&wake_consumed, 1, 0)) {
        vad_voice_streak = 0;
        vad_last_voice_ms = k_uptime_get();
        vad_is_recording = false;
        LOG_INF("AAD: WAKE, VAD reset");
    }

    uint32_t avg = avg_abs_amplitude(buffer, sample_count);
    int64_t now = k_uptime_get();
    bool has_voice = avg >= CONFIG_OMI_VAD_ABS_THRESHOLD;

    if (has_voice) {
        vad_last_voice_ms = now;
        if (!vad_is_recording) {
            vad_voice_streak++;
            if (vad_voice_streak >= CONFIG_OMI_VAD_DEBOUNCE_FRAMES) {
                preroll_queue_flush();
                vad_is_recording = true;
                vad_sleeping = false;
                LOG_INF("VAD: RECORDING (avg=%u)", avg);
            }
        }
    } else {
        vad_voice_streak = 0;
        if (vad_is_recording) {
            int64_t silent_ms = now - vad_last_voice_ms;
            if (silent_ms >= CONFIG_OMI_VAD_HOLD_MS) {
                vad_is_recording = false;
                vad_sleeping = true;
                LOG_INF("VAD: SLEEP (silent %lld ms)", silent_ms);
                preroll_reset();
            }
        }
    }

    /* Periodic status log */
    if (now >= vad_next_status_ms) {
        LOG_INF("VAD: %s (avg=%u thr=%u deb=%u hold=%d)",
                vad_is_recording ? "REC" : "SLEEP",
                avg,
                CONFIG_OMI_VAD_ABS_THRESHOLD,
                CONFIG_OMI_VAD_DEBOUNCE_FRAMES,
                CONFIG_OMI_VAD_HOLD_MS);
        vad_next_status_ms = now + VAD_STATUS_LOG_INTERVAL_MS;
    }

    if (!vad_is_recording) {
        preroll_store(buffer);
        return false;
    }

    /* While replaying pre-roll, output only queued pre-roll frames
     * at the same one-frame-per-callback cadence as normal recording.
     * This avoids interleaving historical frames with current live frames
     * (which corrupts temporal ordering). */
    if (vad_preroll_flush_pending > 0) {
        /* Preserve current live frame while we replay pre-roll. */
        if (!live_backlog_push(buffer)) {
            return false;
        }
        preroll_push_one();
        return false;
    }

    /* Once pre-roll replay has started, keep a single-frame cadence:
     * flush one queued live frame, then queue current frame.
     * This preserves FIFO ordering and avoids two-frame bursts into codec. */
    if (vad_live_backlog_cnt > 0) {
        live_backlog_flush_one();
        if (!live_backlog_push(buffer)) {
            return false;
        }
        return false;
    }

    return true;
}

int aad_start(void)
{
    int ret;

    if (!gpio_is_ready_dt(&pin_wake)) {
        LOG_ERR("AAD: WAKE gpio not ready");
        return -ENODEV;
    }

    ret = gpio_pin_configure_dt(&pin_wake, GPIO_INPUT | GPIO_PULL_DOWN);
    if (ret) {
        LOG_ERR("AAD: WAKE pin config failed (%d)", ret);
        return ret;
    }

    gpio_init_callback(&wake_cb_data, wake_pin_isr, BIT(pin_wake.pin));
    ret = gpio_add_callback(pin_wake.port, &wake_cb_data);
    if (ret) {
        LOG_ERR("AAD: WAKE callback failed (%d)", ret);
        return ret;
    }

    ret = gpio_pin_interrupt_configure_dt(&pin_wake, GPIO_INT_EDGE_RISING);
    if (ret) {
        LOG_ERR("AAD: WAKE IRQ config failed (%d)", ret);
        return ret;
    }

    aad_tid = k_thread_create(&aad_thread_data,
                              aad_stack,
                              K_THREAD_STACK_SIZEOF(aad_stack),
                              aad_thread_fn,
                              NULL,
                              NULL,
                              NULL,
                              AAD_THREAD_PRIORITY,
                              0,
                              K_NO_WAIT);
    k_thread_name_set(aad_tid, "aad");

    LOG_INF("AAD: started (WAKE=P1.%d, thr=%d deb=%d hold=%d)",
            pin_wake.pin,
            CONFIG_OMI_VAD_ABS_THRESHOLD,
            CONFIG_OMI_VAD_DEBOUNCE_FRAMES,
            CONFIG_OMI_VAD_HOLD_MS);
    return 0;
}

bool aad_is_sleeping(void)
{
    return vad_sleeping;
}
```

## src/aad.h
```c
/*
 * AAD + VAD gate for Omi
 *
 * Monitors WAKE pin (P1.2) via GPIO ISR, runs VAD state machine,
 * and manages SD card suspend/resume in a background thread.
 */

#ifndef AAD_H
#define AAD_H

#include <stdbool.h>
#include <stddef.h>
#include <stdint.h>

/**
 * @brief Start AAD handler: configure WAKE pin ISR and spawn thread.
 *
 * Call once after mic_start().
 *
 * @return 0 on success, negative errno on failure
 */
int aad_start(void);

/**
 * @brief Process a mic buffer through the VAD gate.
 *
 * Called from the mic callback.  Handles debounce, pre-roll
 * buffering, and SD suspend/resume.
 *
 * @param buffer       Raw PCM samples from the microphone
 * @param sample_count Number of samples in @p buffer
 * @return true  if the frame contains voice — caller should forward to codec
 * @return false if in VAD sleep — frame stored in pre-roll, skip codec
 */
bool aad_process_audio(int16_t *buffer, size_t sample_count);

/**
 * @brief Check if VAD is in sleep mode (low-power).
 *
 * @return true  if VAD is sleeping (mic paused, T5838 hw AAD active)
 * @return false if VAD is active / recording
 */
bool aad_is_sleeping(void);

#endif /* AAD_H */
```

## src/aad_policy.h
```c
#ifndef OMI_AAD_POLICY_H
#define OMI_AAD_POLICY_H

#include <stdbool.h>
#include <stdint.h>

struct aad_policy_inputs {
    bool connected_quiet_enabled;
    bool retention_enabled;
    bool connected;
    bool subscribed;
    bool live_mode;
    bool charging;
    bool transfer_active;
};

/* Behavior matrix (audio only; never changes BLE parameters or subscriptions):
 * disconnected: existing offline AAD hold;
 * connected/live/subscribed: speech resets the timer, quiet uses the long hold;
 * connected/continuous recording: no hardware sleep;
 * connected/live/unsubscribed: long hold only with durable retention;
 * charging: existing AAD policy, independent of this opt-in feature;
 * storage sync: existing veto in every mode.
 * CCC alone cannot distinguish phone-side Transcribe Later from live capture.
 * The session therefore defaults to continuous recording until explicitly set
 * to live by the central. Zero means that sleep is forbidden.
 */
static inline int64_t aad_policy_timeout(const struct aad_policy_inputs *in, int64_t offline_ms, int64_t live_ms)
{
    if (in->transfer_active) {
        return 0;
    }
    if (!in->connected_quiet_enabled || in->charging || !in->connected) {
        return offline_ms;
    }
    return in->live_mode && (in->subscribed || in->retention_enabled) ? live_ms : 0;
}

#endif
```

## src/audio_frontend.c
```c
#include "audio_frontend.h"

#define INPUT_CHANNELS 2U
#define OUTPUTS_PER_INPUT 2U

size_t audio_frontend_8k_stereo_to_16k_mono(struct audio_frontend_state *state,
                                            const int16_t *interleaved,
                                            size_t input_frames,
                                            int16_t *mono_output,
                                            size_t output_capacity)
{
    if (state == NULL || interleaved == NULL || mono_output == NULL || input_frames == 0U ||
        output_capacity < input_frames * OUTPUTS_PER_INPUT) {
        return 0U;
    }

    size_t output_frame = 0U;
    for (size_t input_frame = 0U; input_frame < input_frames; ++input_frame) {
        size_t input = input_frame * INPUT_CHANNELS;
        int32_t mixed = (int32_t) interleaved[input] + (int32_t) interleaved[input + 1U];
        int16_t mono = (int16_t) (mixed / 2);

        if (!state->seeded) {
            state->previous_mono = mono;
            state->seeded = true;
        }

        mono_output[output_frame++] = (int16_t) (((int32_t) state->previous_mono + (int32_t) mono) / 2);
        mono_output[output_frame++] = mono;
        state->previous_mono = mono;
    }

    return output_frame;
}
```

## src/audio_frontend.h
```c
#ifndef AUDIO_FRONTEND_H
#define AUDIO_FRONTEND_H

#include <stdbool.h>
#include <stddef.h>
#include <stdint.h>

struct audio_frontend_state {
    int16_t previous_mono;
    bool seeded;
};

/*
 * Mix 8 kHz interleaved stereo PCM to mono and linearly interpolate it to
 * 16 kHz. The state preserves the previous sample across DMA block boundaries.
 * Returns the number of mono output frames, or zero for invalid arguments.
 */
size_t audio_frontend_8k_stereo_to_16k_mono(struct audio_frontend_state *state,
                                            const int16_t *interleaved,
                                            size_t input_frames,
                                            int16_t *mono_output,
                                            size_t output_capacity);

#endif /* AUDIO_FRONTEND_H */
```

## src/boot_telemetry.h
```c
/* Owns the boot/update/storage diagnostics contract and its stable persisted wire format. */
#ifndef OMI_BOOT_TELEMETRY_H
#define OMI_BOOT_TELEMETRY_H

#include <stdbool.h>
#include <stddef.h>
#include <stdint.h>

#define OMI_BOOT_RECORD_SIZE 80U
#define OMI_BOOT_SAVE_INTERVAL_MS 600000LL
#define OMI_BOOT_FW_SIZE 16U

enum omi_update_outcome {
    OMI_UPDATE_UNKNOWN = 0,
    OMI_UPDATE_UNCHANGED = 1,
    OMI_UPDATE_UPDATED = 2,
    OMI_UPDATE_NOT_INSTALLED = 3,
};

/* Also the wire flags. Header validity is tracked independently for each boot. */
#define OMI_BOOT_VALID 1U
#define OMI_BOOT_SAFE 2U
#define OMI_BOOT_HEADER_VALID 4U
#define OMI_BOOT_PREVIOUS_HEADER_VALID 8U
#define OMI_BOOT_PREVIOUS_VALID 16U

struct omi_image_identity {
    char fw[OMI_BOOT_FW_SIZE];
    uint8_t header_version[8]; /* major, minor, revision LE16, build LE32 */
};

struct omi_boot_record {
    uint8_t flags;
    uint8_t outcome;
    bool pending_before_boot;
    uint32_t boot_count;
    uint32_t reset_reason;
    uint32_t last_fatal; /* 0 none observed, 1 fatal observed; existing retained signal */
    uint32_t safe_reason;
    uint32_t nor_read_failures;
    uint32_t sd_init_failures;
    struct omi_image_identity current;
    struct omi_image_identity previous;
    bool upload_pending;
};

uint32_t omi_counter_increment(uint32_t value);
enum omi_update_outcome omi_update_classify(const struct omi_boot_record *previous,
                                            const struct omi_image_identity *running,
                                            bool header_valid);
bool omi_boot_save_due(bool dirty, bool attempted, int64_t last_attempt_ms, int64_t now_ms);
/* Stable settings and appended recovery wire format; decode rejects unsupported formats and invalid fields. */
void omi_boot_record_encode(uint8_t out[OMI_BOOT_RECORD_SIZE], const struct omi_boot_record *record);
bool omi_boot_record_decode(struct omi_boot_record *record, const uint8_t *data, size_t len);

/* Thread-context APIs. No flash writes in increment/snapshot paths. */
void omi_boot_telemetry_start(uint32_t reset_reason, bool fatal, bool safe, uint32_t safe_reason);
void omi_boot_telemetry_open(void); /* isolated settings read, once backend access is permitted */
void omi_boot_telemetry_upload_pending(void);
void omi_boot_telemetry_poll(void);
void omi_boot_telemetry_snapshot(struct omi_boot_record *record);
void omi_boot_telemetry_nor_failure(void);
void omi_boot_telemetry_sd_failure(void);

#endif
```
